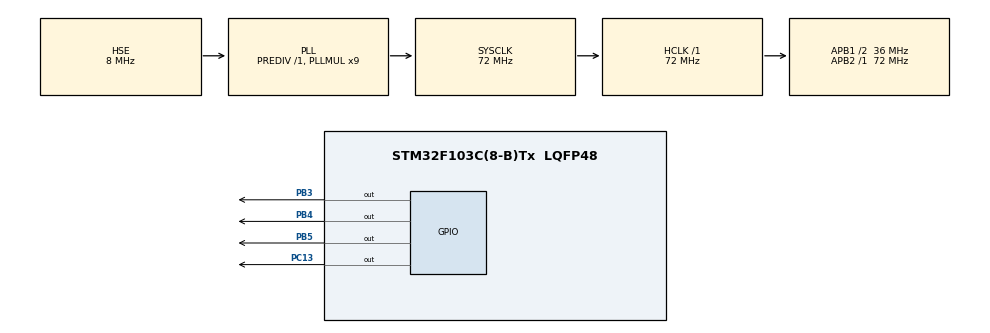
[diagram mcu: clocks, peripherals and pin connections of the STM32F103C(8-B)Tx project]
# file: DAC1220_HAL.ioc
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Mcu.Family=STM32F1
Mcu.Name=STM32F103C(8-B)Tx
Mcu.Package=LQFP48
NVIC.PriorityGroup=NVIC_PRIORITYGROUP_4
PA13.Mode=Serial_Wire
PA13.Signal=SYS_JTMS-SWDIO
PA14.Mode=Serial_Wire
PA14.Signal=SYS_JTCK-SWCLK
PB3.GPIO_ModeDefaultOutputPP=GPIO_MODE_OUTPUT_PP
PB3.GPIO_PuPd=GPIO_NOPULL
PB3.GPIO_Speed=GPIO_SPEED_FREQ_HIGH
PB3.PinState=GPIO_PIN_SET
PB3.Signal=GPIO_Output
PB4.GPIO_PuPd=GPIO_NOPULL
PB4.GPIO_Speed=GPIO_SPEED_FREQ_HIGH
PB4.PinState=GPIO_PIN_SET
PB4.Signal=GPIO_Output
PB5.GPIO_PuPd=GPIO_NOPULL
PB5.GPIO_Speed=GPIO_SPEED_FREQ_HIGH
PB5.PinState=GPIO_PIN_SET
PB5.Signal=GPIO_Output
PC13-TAMPER-RTC.Signal=GPIO_Output
PD0-OSC_IN.Mode=HSE-External-Oscillator
PD0-OSC_IN.Signal=RCC_OSC_IN
PD1-OSC_OUT.Mode=HSE-External-Oscillator
PD1-OSC_OUT.Signal=RCC_OSC_OUT
ProjectManager.HeapSize=0x200
ProjectManager.StackSize=0x400
ProjectManager.TargetToolchain=MDK-ARM V5.32
RCC.AHBFreq_Value=72000000
RCC.APB1CLKDivider=RCC_HCLK_DIV2
RCC.APB1Freq_Value=36000000
RCC.APB1TimFreq_Value=72000000
RCC.APB2Freq_Value=72000000
RCC.APB2TimFreq_Value=72000000
RCC.HCLKFreq_Value=72000000
RCC.PLLMUL=RCC_PLL_MUL9
RCC.PLLSourceVirtual=RCC_PLLSOURCE_HSE
RCC.SYSCLKFreq_VALUE=72000000
RCC.SYSCLKSource=RCC_SYSCLKSOURCE_PLLCLK
RCC.USBFreq_Value=72000000
board=custom

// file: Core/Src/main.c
/* USER CODE BEGIN Header */
/**
  ******************************************************************************
  * @file           : main.c
  * @brief          : Main program body
  ******************************************************************************
  * @attention
  *
  * Copyright (c) 2026 STMicroelectronics.
  * All rights reserved.
  *
  * This software is licensed under terms that can be found in the LICENSE file
  * in the root directory of this software component.
  * If no LICENSE file comes with this software, it is provided AS-IS.
  *
  ******************************************************************************
  */
/* USER CODE END Header */
#include "main.h"
#include "gpio.h"

/* USER CODE BEGIN Includes */
#include "main.h"
#include "DAC1220.h"
/* USER CODE END Includes */

void SystemClock_Config(void);

int main(void)
{

  /* MCU Configuration--------------------------------------------------------*/

  /* Reset of all peripherals, Initializes the Flash interface and the Systick. */
  HAL_Init();

  /* Configure the system clock */
  SystemClock_Config();

  /* Initialize all configured peripherals */
  MX_GPIO_Init();
  /* USER CODE BEGIN 2 */

	uint8_t i=DAC1220_Init();
	float voltage = -10.0f;
  int8_t step = 1;          // 电压增减方向：+1 或 -1
  uint16_t tri_index = 0;   // 三角波表索引
	HAL_GPIO_WritePin(GPIOC,GPIO_PIN_13,!i);
  /* USER CODE END 2 */

  /* Infinite loop */
  while (1)
  {

    /* USER CODE BEGIN 3 */
		// ========== 测试模式 1：线性扫描电压 ==========
        // 输出电压从 -10V 到 +10V 步进，步长 0.1V，每步延时 50ms
//        DAC1220_VoltageOutput(voltage);
//        HAL_Delay(50);          // 改变延时即可改变扫描速度
//
//        voltage += 0.1f * step;
//        if (voltage >= 10.0f) {
//            voltage = 9.9f;
//            step = -1;
//        } else if (voltage <= -10.0f) {
//            voltage = -9.9f;
//            step = 1;
//        }

        // ========== 测试模式 2：三角波输出（如需使用，请注释上面的代码，取消下面注释） ==========

        DAC1220_WDAT(TriangleWave_Value[tri_index]);
        tri_index++;
        if (tri_index >= 256) tri_index = 0;
        HAL_Delay(1);
  }
  /* USER CODE END 3 */
}

void SystemClock_Config(void)
{
  RCC_OscInitTypeDef RCC_OscInitStruct = {0};
  RCC_ClkInitTypeDef RCC_ClkInitStruct = {0};

  /** Initializes the RCC Oscillators according to the specified parameters
  * in the RCC_OscInitTypeDef structure.
  */
  RCC_OscInitStruct.OscillatorType = RCC_OSCILLATORTYPE_HSE;
  RCC_OscInitStruct.HSEState = RCC_HSE_ON;
  RCC_OscInitStruct.HSEPredivValue = RCC_HSE_PREDIV_DIV1;
  RCC_OscInitStruct.HSIState = RCC_HSI_ON;
  RCC_OscInitStruct.PLL.PLLState = RCC_PLL_ON;
  RCC_OscInitStruct.PLL.PLLSource = RCC_PLLSOURCE_HSE;
  RCC_OscInitStruct.PLL.PLLMUL = RCC_PLL_MUL9;
  if (HAL_RCC_OscConfig(&RCC_OscInitStruct) != HAL_OK)
  {
    Error_Handler();
  }

  /** Initializes the CPU, AHB and APB buses clocks
  */
  RCC_ClkInitStruct.ClockType = RCC_CLOCKTYPE_HCLK|RCC_CLOCKTYPE_SYSCLK
                              |RCC_CLOCKTYPE_PCLK1|RCC_CLOCKTYPE_PCLK2;
  RCC_ClkInitStruct.SYSCLKSource = RCC_SYSCLKSOURCE_PLLCLK;
  RCC_ClkInitStruct.AHBCLKDivider = RCC_SYSCLK_DIV1;
  RCC_ClkInitStruct.APB1CLKDivider = RCC_HCLK_DIV2;
  RCC_ClkInitStruct.APB2CLKDivider = RCC_HCLK_DIV1;

  if (HAL_RCC_ClockConfig(&RCC_ClkInitStruct, FLASH_LATENCY_2) != HAL_OK)
  {
    Error_Handler();
  }
}

void Error_Handler(void)
{
  __disable_irq();
  while (1)
  {
  }
}
